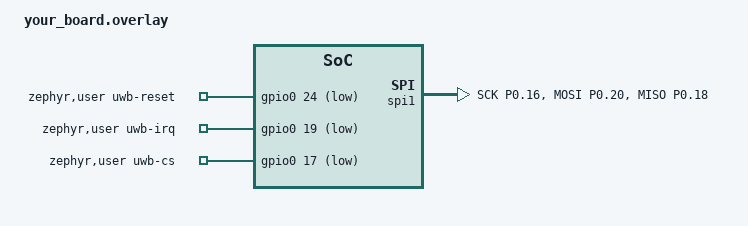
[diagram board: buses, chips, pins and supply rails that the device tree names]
/ {
    zephyr,user {
        /* DWM1001 reference pins from the official nrf52_dwm1001 board DTS. */
        uwb-reset-gpios = <&gpio0 24 GPIO_ACTIVE_LOW>;
        uwb-irq-gpios = <&gpio0 19 (GPIO_PULL_UP | GPIO_ACTIVE_LOW)>;
        uwb-cs-gpios = <&gpio0 17 (GPIO_PULL_UP | GPIO_ACTIVE_LOW)>;
    };
};

&pinctrl {
    spi1_default: spi1_default {
        group1 {
            psels = <NRF_PSEL(SPIM_SCK, 0, 16)>,
                    <NRF_PSEL(SPIM_MOSI, 0, 20)>,
                    <NRF_PSEL(SPIM_MISO, 0, 18)>;
        };
    };

    spi1_sleep: spi1_sleep {
        group1 {
            psels = <NRF_PSEL(SPIM_SCK, 0, 16)>,
                    <NRF_PSEL(SPIM_MOSI, 0, 20)>,
                    <NRF_PSEL(SPIM_MISO, 0, 18)>;
            low-power-enable;
        };
    };
};

&spi1 {
    compatible = "nordic,nrf-spim";
    status = "okay";
    pinctrl-0 = <&spi1_default>;
    pinctrl-1 = <&spi1_sleep>;
    pinctrl-names = "default", "sleep";
};
